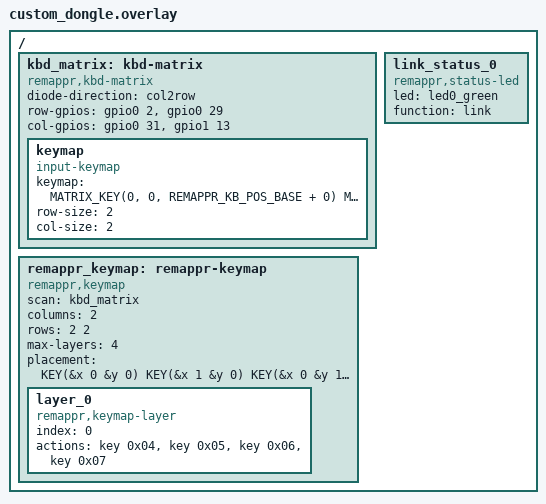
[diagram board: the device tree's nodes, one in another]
/*
 * Custom Dongle Pad — Remappr shield (generated by remappr).
 *
 * Drop this directory into a remappr-firmware checkout under
 * boards/shields/custom_dongle/ and build with -D<app>_SHIELD=custom_dongle. Verify the
 * row/col GPIO specs against your wiring — remappr derives the matrix
 * cells from physical key position, not the electrical matrix.
 *
 * SPDX-License-Identifier: Apache-2.0
 */

#include <zephyr/dt-bindings/input/input-event-codes.h>
#include <zephyr/dt-bindings/input/keymap.h>
#include <dt-bindings/remappr/keys.h>
#include <dt-bindings/remappr/layout.h>
#include <remappr/keymap-tokens.dtsi>
#include <remappr/behavior-tokens.dtsi>

/ {
	kbd_matrix: kbd-matrix {
		compatible = "remappr,kbd-matrix";
		diode-direction = "col2row";
		row-gpios =
			<&gpio0 2 (GPIO_ACTIVE_HIGH | GPIO_PULL_DOWN)>,
			<&gpio0 29 (GPIO_ACTIVE_HIGH | GPIO_PULL_DOWN)>;
		col-gpios =
			<&gpio0 31 GPIO_ACTIVE_HIGH>,
			<&gpio1 13 GPIO_ACTIVE_HIGH>;

		keymap {
			compatible = "input-keymap";
			keymap = <
				MATRIX_KEY(0, 0, REMAPPR_KB_POS_BASE + 0) MATRIX_KEY(0, 1, REMAPPR_KB_POS_BASE + 1)
				MATRIX_KEY(1, 0, REMAPPR_KB_POS_BASE + 2) MATRIX_KEY(1, 1, REMAPPR_KB_POS_BASE + 3)
			>;
			row-size = <2>;
			col-size = <2>;
		};
	};

	remappr_keymap: remappr-keymap {
		compatible = "remappr,keymap";
		scan = <&kbd_matrix>;
		columns = <2>;
		rows = <2 2>;
		max-layers = <4>;
		placement = <
				KEY(&x 0 &y 0) KEY(&x 1 &y 0)
				KEY(&x 0 &y 1) KEY(&x 1 &y 1)
		>;
		layer_0 {
			compatible = "remappr,keymap-layer";
			index = <0>;
			actions = <
				&key 0x04 &key 0x05
				&key 0x06 &key 0x07
			>;
		};
	};
};

/ {
	link_status_0 {
		compatible = "remappr,status-led";
		led = <&led0_green>;
		function = "link";
	};
};
